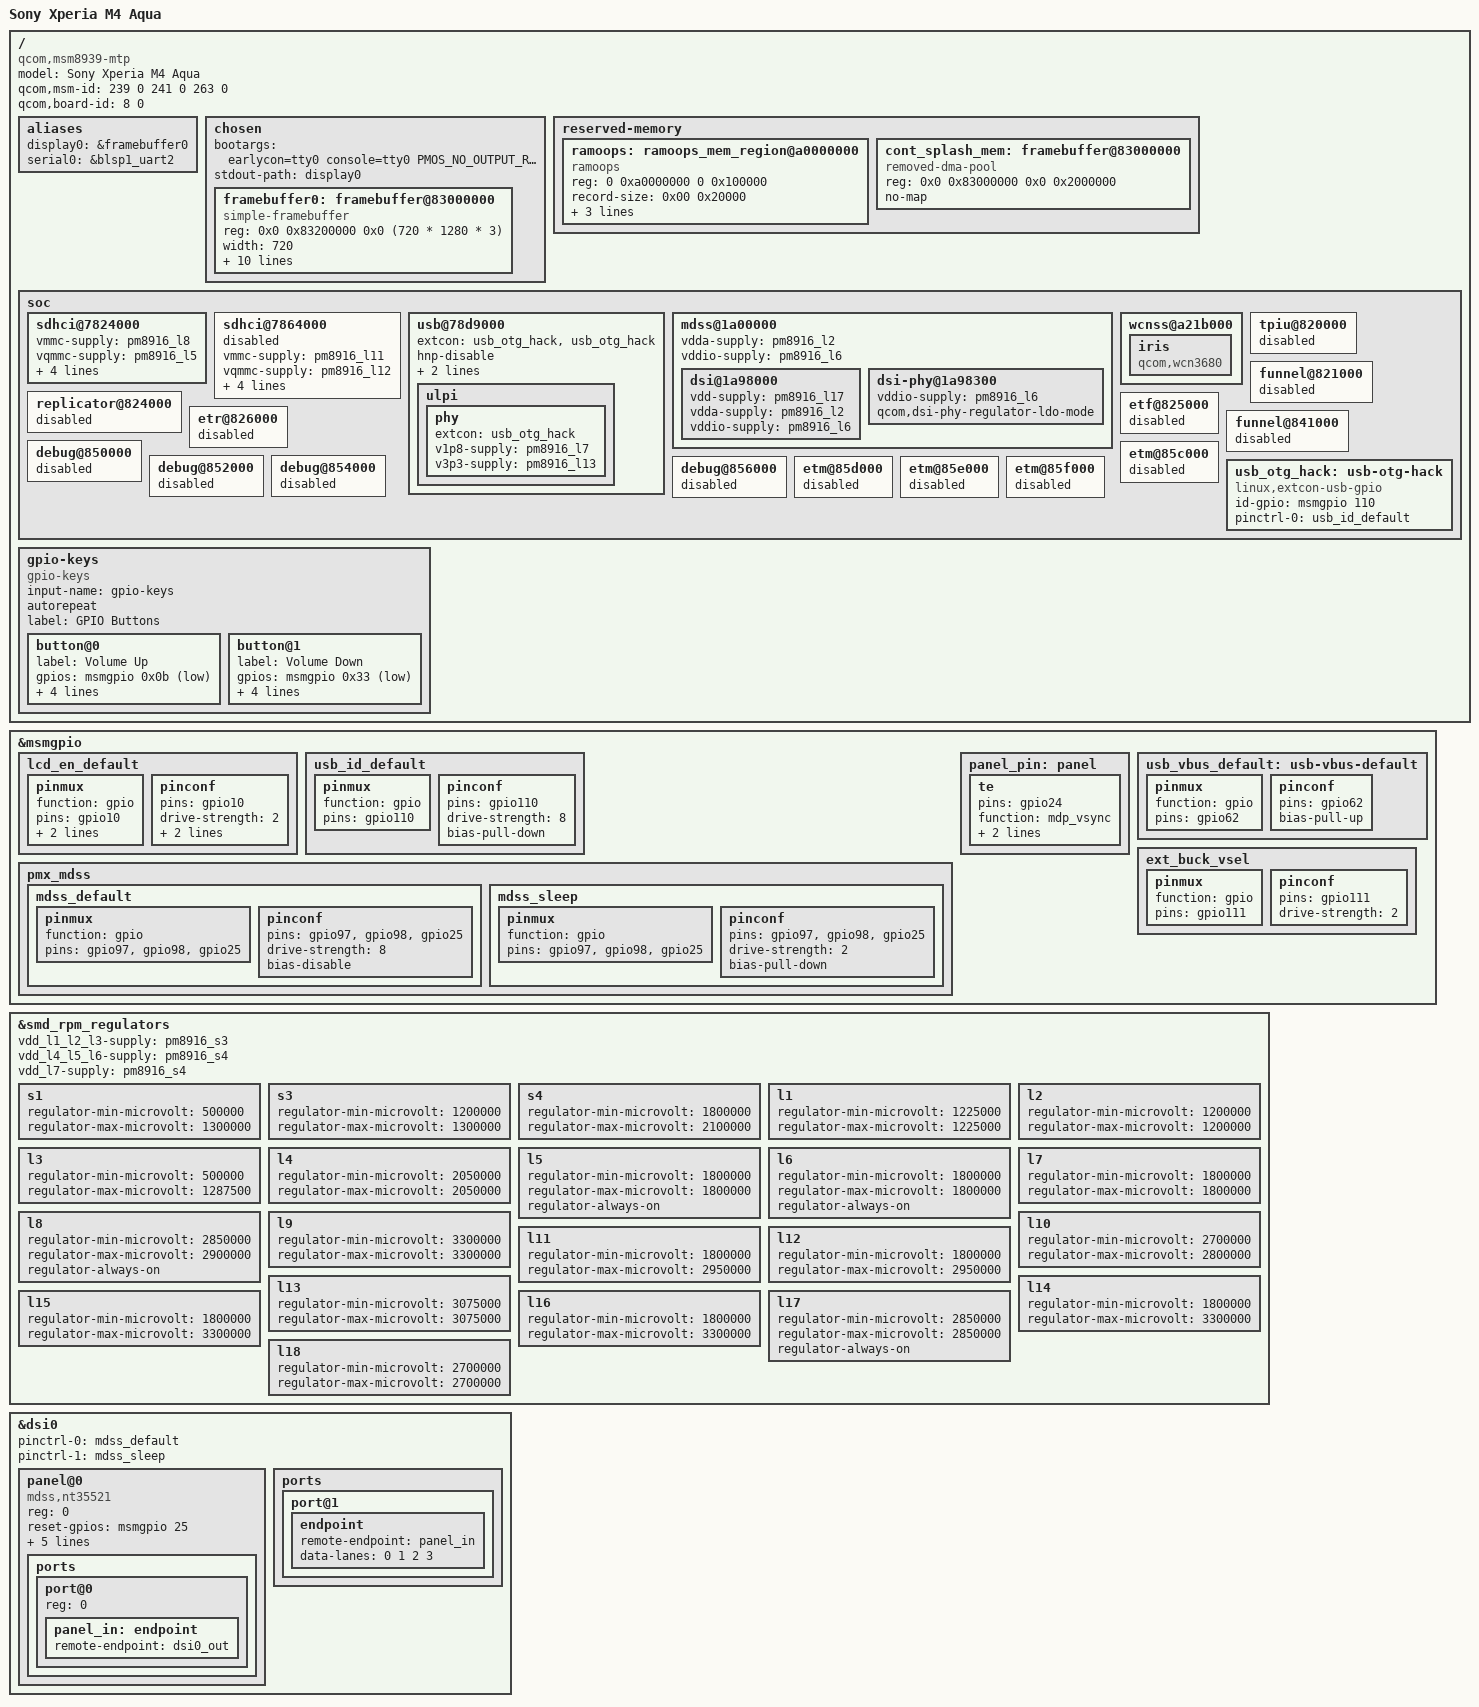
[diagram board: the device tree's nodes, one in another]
// SPDX-License-Identifier: GPL-2.0-only

/dts-v1/;

#include "msm8939.dtsi"
#include "pm8916.dtsi"
#include <dt-bindings/gpio/gpio.h>
#include <dt-bindings/input/input.h>

/ {
	model = "Sony Xperia M4 Aqua";
	compatible = "qcom,msm8939-mtp", "qcom,msm8939", "qcom,mtp";
   	qcom,msm-id = <239 0 241 0 263 0>;
   	qcom,board-id = <8 0>;

	aliases {
		display0 = &framebuffer0;
		serial0 = &blsp1_uart2;
	};

	chosen {
	bootargs = "earlycon=tty0 console=tty0 PMOS_NO_OUTPUT_REDIRECT";
        stdout-path = "display0";

        #address-cells = <2>;
        #size-cells = <2>;
        ranges;

		framebuffer0: framebuffer@83000000 {
				status= "ok";
				compatible = "simple-framebuffer";
				reg = <0x0 0x83200000 0x0 (720 * 1280 * 3)>;
				width = <720>;
				height = <1280>;
				stride = <(720 * 3)>;
				format = "r8g8b8";
				power-domains = <&gcc MDSS_GDSC>;
				clocks = <&gcc GCC_MDSS_AHB_CLK>,
						<&gcc GCC_MDSS_VSYNC_CLK>,
						<&gcc GCC_MDSS_AXI_CLK>,
						<&gcc GCC_MDSS_MDP_CLK>,
						<&gcc GCC_MDSS_BYTE0_CLK>,
						<&gcc GCC_MDSS_PCLK0_CLK>,
						<&gcc GCC_MDSS_ESC0_CLK>,
						<&xo_board>;
		};
	};

	reserved-memory {
		ramoops: ramoops_mem_region@a0000000 {
			compatible = "ramoops";
			reg = <0 0xa0000000 0 0x100000>;

			record-size = <0x00 0x20000>;
			console-size = <0x00 0x40000>;
			ftrace-size = <0x00 0x20000>;
			pmsg-size = <0x00 0x20000>;
			status = "ok";
		};

		cont_splash_mem: framebuffer@83000000 {
			compatible = "removed-dma-pool";
			reg = <0x0 0x83000000 0x0 0x2000000>;
			no-map;
		};
	};

	soc {
		sdhci@7824000 {
			status = "okay";

			vmmc-supply = <&pm8916_l8>;
			vqmmc-supply = <&pm8916_l5>;

			pinctrl-names = "default", "sleep";
			pinctrl-0 = <&sdc1_clk_on &sdc1_cmd_on &sdc1_data_on>;
			pinctrl-1 = <&sdc1_clk_off &sdc1_cmd_off &sdc1_data_off>;
		};

		//Enabling this node breaks touchscreen driver.
		sdhci@7864000 {
			status = "disabled";

			vmmc-supply = <&pm8916_l11>;
			vqmmc-supply = <&pm8916_l12>;

			pinctrl-names = "default", "sleep";
			pinctrl-0 = <&sdc2_clk_on &sdc2_cmd_on &sdc2_data_on>;
			pinctrl-1 = <&sdc2_clk_off &sdc2_cmd_off &sdc2_data_off>;
		};

		usb@78d9000 {
			status = "okay";
			extcon = <&usb_otg_hack>, <&usb_otg_hack>;

			hnp-disable;
			srp-disable;
			adp-disable;

			ulpi {
				phy {
					extcon = <&usb_otg_hack>;
					v1p8-supply = <&pm8916_l7>;
					v3p3-supply = <&pm8916_l13>;
				};
			};
		};

		mdss@1a00000 {
			vdda-supply = <&pm8916_l2>;
			vddio-supply = <&pm8916_l6>;
			status = "ok";
			dsi@1a98000 {
				#address-cells = <1>;
				#size-cells = <0>;

				vdd-supply = <&pm8916_l17>;
				vdda-supply = <&pm8916_l2>;
				vddio-supply = <&pm8916_l6>;
			};

			dsi-phy@1a98300 {
				vddio-supply = <&pm8916_l6>;
				qcom,dsi-phy-regulator-ldo-mode;
			};
		};

		wcnss@a21b000 {
			//status = "okay";

			iris {
				compatible = "qcom,wcn3680";
			};
		};

		/*
		 * Attempting to enable these devices causes a "synchronous
		 * external abort". Suspected cause is that the debug power
		 * domain is not enabled by default on this device.
		 * Disable these devices for now to avoid the crash.
		 *
		 * See: https://lore.kernel.org/linux-arm-msm/20190618202623.GA53651@gerhold.net/
		 */
		tpiu@820000 { status = "disabled"; };
		funnel@821000 { status = "disabled"; };
		replicator@824000 { status = "disabled"; };
		etf@825000 { status = "disabled"; };
		etr@826000 { status = "disabled"; };
		funnel@841000 { status = "disabled"; };
		debug@850000 { status = "disabled"; };
		debug@852000 { status = "disabled"; };
		debug@854000 { status = "disabled"; };
		debug@856000 { status = "disabled"; };
		etm@85c000 { status = "disabled"; };
		etm@85d000 { status = "disabled"; };
		etm@85e000 { status = "disabled"; };
		etm@85f000 { status = "disabled"; };

		// FIXME: Use extcon device provided by charger driver when available
	usb_otg_hack: usb-otg-hack {
		compatible = "linux,extcon-usb-gpio";

		/*
		 * NOTE: This allows detection of custom-made OTG adapters
		 *
		 * Since L8150 doesn't support OTG it's impossible to use normal OTG
		 * adapters. However since USB_ID is in fact connected to GPIO it's
		 * possible to detect custom-made OTG adapters that connect USB_ID
		 * to 5v instead of GND and provie external power.
		 *
		 * Downside of this approach is that USB_ID pin is used to change boot
		 * order of SoC and if device will be powered on with adapter attached
		 * and powered, it will boot into USB BOOT mode.
		 */
		id-gpio = <&msmgpio 110 0>;
		pinctrl-names = "default";
		pinctrl-0 = <&usb_id_default>;
	};
	};

	gpio-keys {
		compatible = "gpio-keys";
		input-name = "gpio-keys";
		#address-cells = <1>;
		#size-cells = <0>;
		autorepeat;

		label = "GPIO Buttons";

		button@0 {
			label = "Volume Up";
			gpios = <&msmgpio 0x0b 1>;
			linux,input-type = <1>;
			linux,code = <KEY_VOLUMEUP>;
			wakeup-source;
			debounce-interval = <15>;
		};

		button@1 {
			label = "Volume Down";
			gpios = <&msmgpio 0x33 1>;
			linux,input-type = <1>;
			linux,code = <KEY_VOLUMEDOWN>;
			wakeup-source;
			debounce-interval = <15>;
		};
	};
};

&msmgpio {
	lcd_en_default: lcd_en_default {
		pinmux {
			function = "gpio";
			pins = "gpio10";
			drive-strength = <8>;
			bias-disable;
		};
		pinconf {
			pins = "gpio10";
			drive-strength = <2>;
			bias-pull-down;
			output-low;
		};
	};

	usb_id_default: usb_id_default {
		pinmux {
			function = "gpio";
			pins = "gpio110";
		};
		pinconf {
			pins = "gpio110";
			drive-strength = <8>;
			bias-pull-down;
		};
	};

	pmx_mdss {
		mdss_default: mdss_default {
			pinmux {
				function = "gpio";
				pins = "gpio97", "gpio98", "gpio25";
			};
			pinconf {
				pins = "gpio97", "gpio98", "gpio25";
				drive-strength = <8>;
				bias-disable;
			};
		};

		mdss_sleep: mdss_sleep {
			pinmux {
				function = "gpio";
				pins = "gpio97", "gpio98", "gpio25";
			};
			pinconf {
				pins = "gpio97", "gpio98", "gpio25";
				drive-strength = <2>;
				bias-pull-down;
			};
		};
	};
	panel_pin: panel {
			te {
				pins = "gpio24";
				function = "mdp_vsync";

				drive-strength = <2>;
				bias-pull-down;
			};
	};

	usb_vbus_default: usb-vbus-default {
		pinmux {
			function = "gpio";
			pins = "gpio62";
		};
		pinconf {
			pins = "gpio62";
			bias-pull-up;
		};
	};

	ext_buck_vsel: ext_buck_vsel {
		pinmux {
			function = "gpio";
			pins = "gpio111";
		};
		pinconf{
			pins = "gpio111";
			drive-strength = <2>;
		};
	};
};

&smd_rpm_regulators {
	vdd_l1_l2_l3-supply = <&pm8916_s3>;
	vdd_l4_l5_l6-supply = <&pm8916_s4>;
	vdd_l7-supply = <&pm8916_s4>;

	s1 {
		regulator-min-microvolt = <500000>;
		regulator-max-microvolt = <1300000>;
	};

	s3 {
		regulator-min-microvolt = <1200000>;
		regulator-max-microvolt = <1300000>;
	};

	s4 {
		regulator-min-microvolt = <1800000>;
		regulator-max-microvolt = <2100000>;
	};

	l1 {
		regulator-min-microvolt = <1225000>;
		regulator-max-microvolt = <1225000>;
	};

	l2 {
		regulator-min-microvolt = <1200000>;
		regulator-max-microvolt = <1200000>;
	};

	l3 {
		regulator-min-microvolt = <500000>;
		regulator-max-microvolt = <1287500>;
	};

	l4 {
		regulator-min-microvolt = <2050000>;
		regulator-max-microvolt = <2050000>;
	};

	l5 {
		regulator-min-microvolt = <1800000>;
		regulator-max-microvolt = <1800000>;
		regulator-always-on;
	};

	l6 {
		regulator-min-microvolt = <1800000>;
		regulator-max-microvolt = <1800000>;
		regulator-always-on;
	};

	l7 {
		regulator-min-microvolt = <1800000>;
		regulator-max-microvolt = <1800000>;
	};

	l8 {
		regulator-min-microvolt = <2850000>;
		regulator-max-microvolt = <2900000>;
		regulator-always-on;
	};

	l9 {
		regulator-min-microvolt = <3300000>;
		regulator-max-microvolt = <3300000>;
	};

	l10 {
		regulator-min-microvolt = <2700000>;
		regulator-max-microvolt = <2800000>;
	};

	l11 {
		regulator-min-microvolt = <1800000>;
		regulator-max-microvolt = <2950000>;
	};

	l12 {
		regulator-min-microvolt = <1800000>;
		regulator-max-microvolt = <2950000>;
	};

	l13 {
		regulator-min-microvolt = <3075000>;
		regulator-max-microvolt = <3075000>;
	};

	l14 {
		regulator-min-microvolt = <1800000>;
		regulator-max-microvolt = <3300000>;
	};

	l15 {
		regulator-min-microvolt = <1800000>;
		regulator-max-microvolt = <3300000>;
	};

	l16 {
		regulator-min-microvolt = <1800000>;
		regulator-max-microvolt = <3300000>;
	};

	l17 {
		regulator-min-microvolt = <2850000>;
		regulator-max-microvolt = <2850000>;
		regulator-always-on;
	};

	l18 {
		regulator-min-microvolt = <2700000>;
		regulator-max-microvolt = <2700000>;
	};
};

&dsi0 {
			pinctrl-names = "default", "sleep";
			pinctrl-0 = <&mdss_default>;
			pinctrl-1 = <&mdss_sleep>;

			panel@0 {
				compatible = "mdss,nt35521";
				reg = <0>;

				reset-gpios = <&msmgpio 25 0>;
				vdd-supply = <&pm8916_l8>;
				vddio-supply = <&pm8916_l6>;

				pinctrl-names = "default";
				pinctrl-0 = <&panel_pin>;
				backlight-gpios = <&msmgpio 10 0>;
				enable-gpios = <&msmgpio 97 0>;

				ports {
					#address-cells = <1>;
					#size-cells = <0>;

					port@0 {
						reg = <0>;
						panel_in: endpoint {
							remote-endpoint = <&dsi0_out>;
						};
					};
				};
			};

			ports {
				port@1 {
					endpoint {
						remote-endpoint = <&panel_in>;
						data-lanes = <0 1 2 3>;
					};
				};
			};
		};
